# WKUP_CM register map
Vendor: Texas Instruments
Peripheral module from a debugger description file (folder omap4460).
Registers are 32-bit, access per field, reset 0x30000 unless marked. A register's access mark holds for its fields unless they carry their own. Offsets are as the file gives them; lines under a group give offsets from that group; [hi:lo] are bit positions; {n}, {i} and the like mark numbered series; 'fields as' and 'values as' point back to an identical list; <NAME> marks a mode.

## WKUP_CM
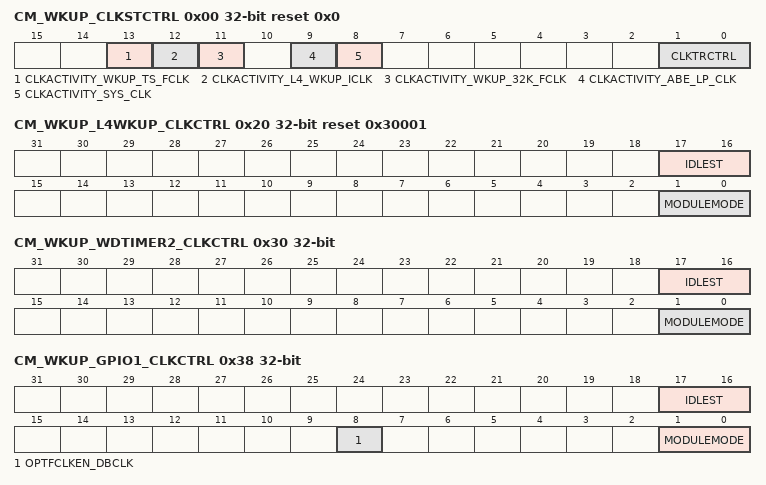
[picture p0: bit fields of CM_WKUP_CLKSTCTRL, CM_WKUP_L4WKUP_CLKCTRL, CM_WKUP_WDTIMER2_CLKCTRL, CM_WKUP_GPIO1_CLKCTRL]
0x00 CM_WKUP_CLKSTCTRL reset 0x0 — This register enables the domain power state transition. It controls the hardware supervised domain power state transition between ON-ACTIVE and ON-INACTIVE states. It also holds 1 status bit per clock input of the domain.
  [13] CLKACTIVITY_WKUP_TS_FCLK ro — This field indicates the state of the WKUP_TS_FCLK clock in the domain. [warm reset insensitive]
    1=CLKACTIVITY_WKUP_TS_FCLK_1_r (Corresponding clock is running or gating/ungating transition is on-going); 0=CLKACTIVITY_WKUP_TS_FCLK_0_r (Corresponding clock is definitely gated)
  [12] CLKACTIVITY_L4_WKUP_ICLK ro — This field indicates the state of the clock in the domain. [warm reset insensitive]
    0=CLKACTIVITY_L4_WKUP_ICLK_0_r (Corresponding clock is definitely gated); 1=CLKACTIVITY_L4_WKUP_ICLK_1_r (Corresponding clock is running or gating/ungating transition is ongoing)
  [11] CLKACTIVITY_WKUP_32K_FCLK ro — This field indicates the state of the clock in the domain. [warm reset insensitive]
    0=CLKACTIVITY_WKUP_32K_FCLK_0_r (Corresponding clock is definitely gated); 1=CLKACTIVITY_WKUP_32K_FCLK_1_r (Corresponding clock is running or gating/ungating transition is ongoing)
  [9] CLKACTIVITY_ABE_LP_CLK ro — This field indicates the state of the clock in the domain. [warm reset insensitive]
    0=CLKACTIVITY_ABE_LP_CLK_0_r (Corresponding clock is definitely gated); 1=CLKACTIVITY_ABE_LP_CLK_1_r (Corresponding clock is running or gating/ungating transition is ongoing)
  [8] CLKACTIVITY_SYS_CLK ro — This field indicates the state of the SYS_CLK clock in the domain. [warm reset insensitive]
    0=CLKACTIVITY_SYS_CLK_0_r (Corresponding clock is definitely gated); 1=CLKACTIVITY_SYS_CLK_1_r (Corresponding clock is running or gating/ungating transition is ongoing)
  [1:0] CLKTRCTRL rw — Controls the clock state transition of the WKUP clock domain.
    0=NO_SLEEP: Sleep transition cannot be initiated. Wakeup transition may however occur.; 1=CLKTRCTRL_1_r (Reserved); 2=CLKTRCTRL_2_r (Reserved); 3=HW_AUTO: Automatic transition is enabled. Sleep and wakeup transition are based upon hardware conditions.
0x20 CM_WKUP_L4WKUP_CLKCTRL access not given reset 0x30001 — This register manages the L4WKUP clocks.
  [17:16] IDLEST ro — Module idle status. [warm reset insensitive]
    0=IDLEST_0_r (Module is fully functional, including INTRCONN); 1=IDLEST_1_r (Module is performing transition: wakeup, or sleep, or sleep abortion); 2=IDLEST_2_r (Module is in idle mode (only INTRCONN part). It is functional if using separate functional clock); 3=IDLEST_3_r (Module is disabled and cannot be accessed)
  [1:0] MODULEMODE — Control the way mandatory clocks are managed. (access R Rreturns)
    1=MODULEMODE_1_r (Module is managed automatically by hardware according to clock domain transition. A clock domain sleep transition put module into idle. A wakeup domain transition put it back into function. If CLKTRCTRL=3, any INTRCONN access to module is always granted. Module clocks may be gated according to the clock domain state.)
0x30 CM_WKUP_WDTIMER2_CLKCTRL — This register manages the WDT2 clocks.
  [17:16] IDLEST ro — Module idle status. [warm reset insensitive]
    values as CM_WKUP_L4WKUP_CLKCTRL.IDLEST
  [1:0] MODULEMODE rw — Control the way mandatory clocks are managed.
    0=Module is disable by software. Any INTRCONN access to module results in an error, except if resulting from a module wakeup (asynchronous wakeup).; 1=MODULEMODE_1_r (Reserved); 2=Module is explicitly enabled. Interface clock (if not used for functions) may be gated according to the clock domain state. Functional clocks are guarantied to stay present. As long as in this configuration, power domain sleep transition cannot happen.; 3=MODULEMODE_3_r (Reserved)
0x38 CM_WKUP_GPIO1_CLKCTRL — This register manages the GPIO1 clocks.
  [17:16] IDLEST ro — Module idle status. [warm reset insensitive]
    values as CM_WKUP_L4WKUP_CLKCTRL.IDLEST
  [8] OPTFCLKEN_DBCLK rw — Optional functional clock control.
    0=Optional functional clock is disabled; 1=Optional functional clock is enabled
  [1:0] MODULEMODE rw — Control the way mandatory clocks are managed.
    0=Module is disable by software. Any INTRCONN access to module results in an error, except if resulting from a module wakeup (asynchronous wakeup).; 1=Module is managed automatically by hardware according to clock domain transition. A clock domain sleep transition put module into idle. A wakeup domain transition put it back into function. If CLKTRCTRL=3, any INTRCONN access to module is always granted. Module clocks may be gated according to the clock domain state.; 2=MODULEMODE_2_r (Reserved); 3=MODULEMODE_3_r (Reserved)
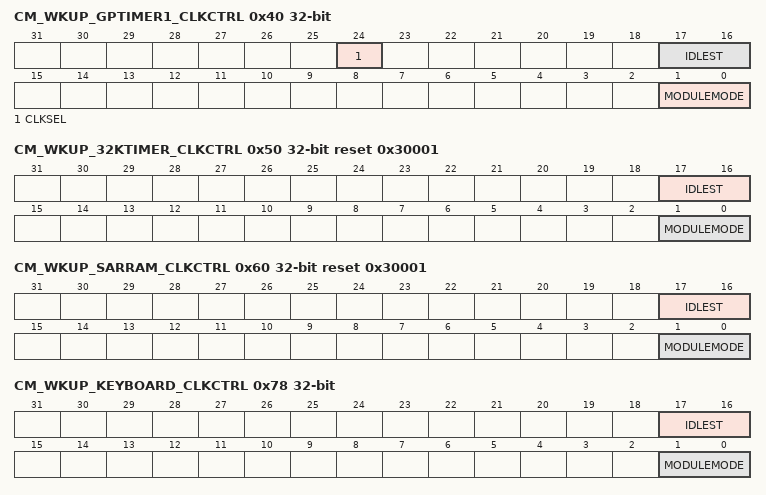
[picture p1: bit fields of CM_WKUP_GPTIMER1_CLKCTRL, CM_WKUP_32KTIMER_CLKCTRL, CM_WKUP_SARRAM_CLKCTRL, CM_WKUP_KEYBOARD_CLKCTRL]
0x40 CM_WKUP_GPTIMER1_CLKCTRL — This register manages the TIMER1 clocks.
  [24] CLKSEL rw — Select the source of the functional clock
    0=Selects the SYS_CLK as the source; 1=Selects the 32KHz as the source
  [17:16] IDLEST ro — Module idle status. [warm reset insensitive]
    values as CM_WKUP_L4WKUP_CLKCTRL.IDLEST
  [1:0] MODULEMODE rw — Control the way mandatory clocks are managed.
    values as CM_WKUP_WDTIMER2_CLKCTRL.MODULEMODE
0x50 CM_WKUP_32KTIMER_CLKCTRL access not given reset 0x30001 — This register manages the SYNCTIMER clocks.
  fields as CM_WKUP_L4WKUP_CLKCTRL
0x60 CM_WKUP_SARRAM_CLKCTRL access not given reset 0x30001 — This register manages the SARRAM clocks.
  [17:16] IDLEST ro — Module idle status. [warm reset insensitive]
    values as CM_WKUP_L4WKUP_CLKCTRL.IDLEST
  [1:0] MODULEMODE — Control the way mandatory clocks are managed. (access R Rreturns)
    1=MODULEMODE_1_r (Module is managed automatically by hadware according to clock domain transition. A clock domain sleep transition put module into idle. A wakeup domain transition put it back into function. If CLKTRCTRL=3, any INTRCONN access to module is always granted. Module clocks may be gated according to the clock domain state.)
0x78 CM_WKUP_KEYBOARD_CLKCTRL — This register manages the KEYBOARD clocks.
  fields as CM_WKUP_WDTIMER2_CLKCTRL
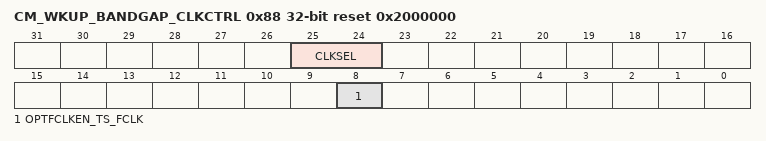
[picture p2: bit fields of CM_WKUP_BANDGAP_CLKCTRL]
0x88 CM_WKUP_BANDGAP_CLKCTRL reset 0x2000000 — This register manages the clock delivered to the Bandgap and SYSCTRL_GENERAL_CORE modules for the Thermal Sensor feature. [warm reset insensitive]
  [25:24] CLKSEL rw — Selects the divider value for generating the Thermal Sensor clock from L4WKUP_ICLK source. The divider has to be selected so as to guarantee a frequency between 1MHz and 2MHz.
    0=Divide by 8; 1=Divide by 16; 2=Divide by 32
  [8] OPTFCLKEN_TS_FCLK rw — Optional functional clock control.
    values as CM_WKUP_GPIO1_CLKCTRL.OPTFCLKEN_DBCLK
